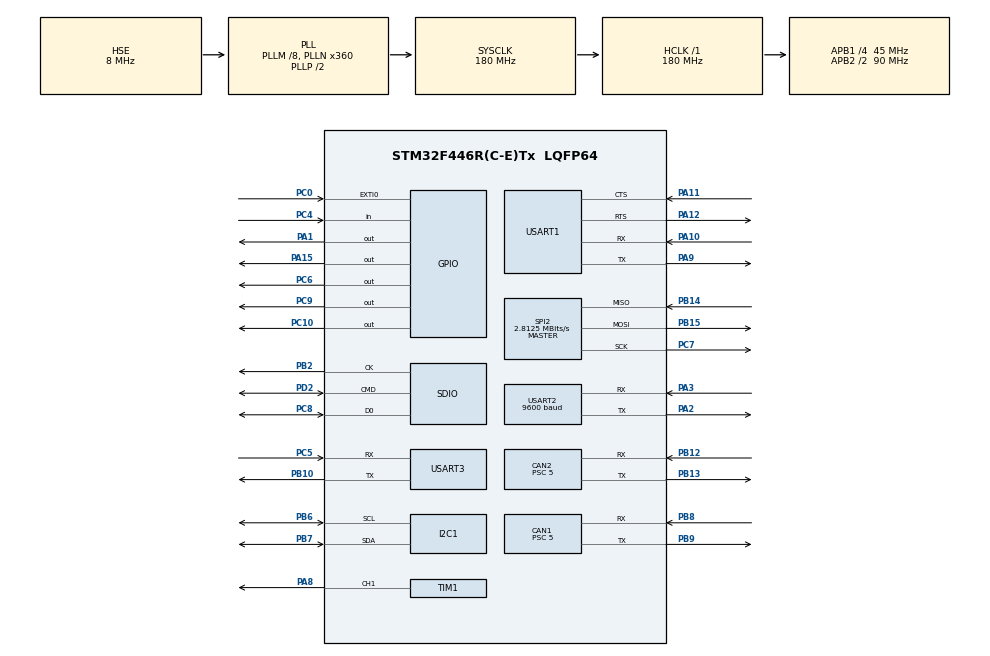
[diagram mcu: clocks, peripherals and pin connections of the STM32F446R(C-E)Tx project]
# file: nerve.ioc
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CAN1.BS1=CAN_BS1_15TQ
CAN1.BS2=CAN_BS2_2TQ
CAN1.CalculateBaudRate=500000
CAN1.CalculateTimeBit=2000
CAN1.CalculateTimeQuantum=111.11111111111111
CAN1.Prescaler=5
CAN2.BS1=CAN_BS1_15TQ
CAN2.BS2=CAN_BS2_2TQ
CAN2.CalculateBaudRate=500000
CAN2.CalculateTimeBit=2000
CAN2.CalculateTimeQuantum=111.11111111111111
CAN2.Prescaler=5
Dma.Request0=SPI2_RX
Dma.Request1=USART1_RX
Dma.Request2=USART1_TX
Dma.Request3=SDIO_RX
Dma.Request4=SDIO_TX
Dma.Request5=TIM1_CH1
Dma.Request6=SPI2_TX
Dma.Request7=USART2_RX
Dma.Request8=USART2_TX
Dma.SDIO_RX.3.Direction=DMA_PERIPH_TO_MEMORY
Dma.SDIO_RX.3.FIFOMode=DMA_FIFOMODE_ENABLE
Dma.SDIO_RX.3.FIFOThreshold=DMA_FIFO_THRESHOLD_FULL
Dma.SDIO_RX.3.Instance=DMA2_Stream3
Dma.SDIO_RX.3.MemBurst=DMA_MBURST_INC4
Dma.SDIO_RX.3.MemDataAlignment=DMA_MDATAALIGN_WORD
Dma.SDIO_RX.3.MemInc=DMA_MINC_ENABLE
Dma.SDIO_RX.3.Mode=DMA_PFCTRL
Dma.SDIO_RX.3.PeriphBurst=DMA_PBURST_INC4
Dma.SDIO_RX.3.PeriphDataAlignment=DMA_PDATAALIGN_WORD
Dma.SDIO_RX.3.PeriphInc=DMA_PINC_DISABLE
Dma.SDIO_RX.3.Priority=DMA_PRIORITY_LOW
Dma.SDIO_TX.4.Direction=DMA_MEMORY_TO_PERIPH
Dma.SDIO_TX.4.FIFOMode=DMA_FIFOMODE_ENABLE
Dma.SDIO_TX.4.FIFOThreshold=DMA_FIFO_THRESHOLD_FULL
Dma.SDIO_TX.4.Instance=DMA2_Stream6
Dma.SDIO_TX.4.MemBurst=DMA_MBURST_INC4
Dma.SDIO_TX.4.MemDataAlignment=DMA_MDATAALIGN_WORD
Dma.SDIO_TX.4.MemInc=DMA_MINC_ENABLE
Dma.SDIO_TX.4.Mode=DMA_PFCTRL
Dma.SDIO_TX.4.PeriphBurst=DMA_PBURST_INC4
Dma.SDIO_TX.4.PeriphDataAlignment=DMA_PDATAALIGN_WORD
Dma.SDIO_TX.4.PeriphInc=DMA_PINC_DISABLE
Dma.SDIO_TX.4.Priority=DMA_PRIORITY_LOW
Dma.SPI2_RX.0.Direction=DMA_PERIPH_TO_MEMORY
Dma.SPI2_RX.0.FIFOMode=DMA_FIFOMODE_DISABLE
Dma.SPI2_RX.0.Instance=DMA1_Stream3
Dma.SPI2_RX.0.MemDataAlignment=DMA_MDATAALIGN_BYTE
Dma.SPI2_RX.0.MemInc=DMA_MINC_ENABLE
Dma.SPI2_RX.0.Mode=DMA_NORMAL
Dma.SPI2_RX.0.PeriphDataAlignment=DMA_PDATAALIGN_BYTE
Dma.SPI2_RX.0.PeriphInc=DMA_PINC_DISABLE
Dma.SPI2_RX.0.Priority=DMA_PRIORITY_LOW
Dma.SPI2_TX.6.Direction=DMA_MEMORY_TO_PERIPH
Dma.SPI2_TX.6.FIFOMode=DMA_FIFOMODE_DISABLE
Dma.SPI2_TX.6.Instance=DMA1_Stream4
Dma.SPI2_TX.6.MemDataAlignment=DMA_MDATAALIGN_BYTE
Dma.SPI2_TX.6.MemInc=DMA_MINC_ENABLE
Dma.SPI2_TX.6.Mode=DMA_NORMAL
Dma.SPI2_TX.6.PeriphDataAlignment=DMA_PDATAALIGN_BYTE
Dma.SPI2_TX.6.PeriphInc=DMA_PINC_DISABLE
Dma.SPI2_TX.6.Priority=DMA_PRIORITY_LOW
Dma.TIM1_CH1.5.Direction=DMA_MEMORY_TO_PERIPH
Dma.TIM1_CH1.5.FIFOMode=DMA_FIFOMODE_DISABLE
Dma.TIM1_CH1.5.Instance=DMA2_Stream1
Dma.TIM1_CH1.5.MemDataAlignment=DMA_MDATAALIGN_HALFWORD
Dma.TIM1_CH1.5.MemInc=DMA_MINC_ENABLE
Dma.TIM1_CH1.5.Mode=DMA_NORMAL
Dma.TIM1_CH1.5.PeriphDataAlignment=DMA_PDATAALIGN_HALFWORD
Dma.TIM1_CH1.5.PeriphInc=DMA_PINC_DISABLE
Dma.TIM1_CH1.5.Priority=DMA_PRIORITY_LOW
Dma.USART1_RX.1.Direction=DMA_PERIPH_TO_MEMORY
Dma.USART1_RX.1.FIFOMode=DMA_FIFOMODE_DISABLE
Dma.USART1_RX.1.Instance=DMA2_Stream2
Dma.USART1_RX.1.MemDataAlignment=DMA_MDATAALIGN_BYTE
Dma.USART1_RX.1.MemInc=DMA_MINC_ENABLE
Dma.USART1_RX.1.Mode=DMA_CIRCULAR
Dma.USART1_RX.1.PeriphDataAlignment=DMA_PDATAALIGN_BYTE
Dma.USART1_RX.1.PeriphInc=DMA_PINC_DISABLE
Dma.USART1_RX.1.Priority=DMA_PRIORITY_HIGH
Dma.USART1_TX.2.Direction=DMA_MEMORY_TO_PERIPH
Dma.USART1_TX.2.FIFOMode=DMA_FIFOMODE_DISABLE
Dma.USART1_TX.2.Instance=DMA2_Stream7
Dma.USART1_TX.2.MemDataAlignment=DMA_MDATAALIGN_BYTE
Dma.USART1_TX.2.MemInc=DMA_MINC_ENABLE
Dma.USART1_TX.2.Mode=DMA_NORMAL
Dma.USART1_TX.2.PeriphDataAlignment=DMA_PDATAALIGN_BYTE
Dma.USART1_TX.2.PeriphInc=DMA_PINC_DISABLE
Dma.USART1_TX.2.Priority=DMA_PRIORITY_HIGH
Dma.USART2_RX.7.Direction=DMA_PERIPH_TO_MEMORY
Dma.USART2_RX.7.FIFOMode=DMA_FIFOMODE_DISABLE
Dma.USART2_RX.7.Instance=DMA1_Stream5
Dma.USART2_RX.7.MemDataAlignment=DMA_MDATAALIGN_BYTE
Dma.USART2_RX.7.MemInc=DMA_MINC_ENABLE
Dma.USART2_RX.7.Mode=DMA_CIRCULAR
Dma.USART2_RX.7.PeriphDataAlignment=DMA_PDATAALIGN_BYTE
Dma.USART2_RX.7.PeriphInc=DMA_PINC_DISABLE
Dma.USART2_RX.7.Priority=DMA_PRIORITY_LOW
Dma.USART2_TX.8.Direction=DMA_MEMORY_TO_PERIPH
Dma.USART2_TX.8.FIFOMode=DMA_FIFOMODE_DISABLE
Dma.USART2_TX.8.Instance=DMA1_Stream6
Dma.USART2_TX.8.MemDataAlignment=DMA_MDATAALIGN_BYTE
Dma.USART2_TX.8.MemInc=DMA_MINC_ENABLE
Dma.USART2_TX.8.Mode=DMA_NORMAL
Dma.USART2_TX.8.PeriphDataAlignment=DMA_PDATAALIGN_BYTE
Dma.USART2_TX.8.PeriphInc=DMA_PINC_DISABLE
Dma.USART2_TX.8.Priority=DMA_PRIORITY_LOW
FATFS.BSP.number=1
FATFS.USE_DMA_CODE_SD=1
FATFS._MAX_SS=4096
FATFS._USE_FIND=1
FATFS._USE_LFN=1
FATFS0.BSP.STBoard=false
FATFS0.BSP.api=Unknown
FATFS0.BSP.instance=PC4
FATFS0.BSP.ip=GPIO
FATFS0.BSP.mode=Input
FATFS0.BSP.name=Detect_SDIO
FATFS0.BSP.solution=PC4
I2C1.I2C_Mode=I2C_Fast
Mcu.Family=STM32F4
Mcu.Name=STM32F446R(C-E)Tx
Mcu.Package=LQFP64
NVIC.CAN1_RX0_IRQn=true\:0\:0\:false\:false\:true\:true\:true\:true
NVIC.CAN1_RX1_IRQn=true\:0\:0\:false\:false\:true\:true\:true\:true
NVIC.CAN2_RX0_IRQn=true\:0\:0\:false\:false\:true\:true\:true\:true
NVIC.CAN2_RX1_IRQn=true\:0\:0\:false\:false\:true\:true\:true\:true
NVIC.DMA1_Stream3_IRQn=true\:1\:1\:true\:false\:true\:false\:true\:true
NVIC.DMA1_Stream4_IRQn=true\:1\:1\:true\:false\:true\:false\:true\:true
NVIC.DMA1_Stream5_IRQn=true\:1\:0\:true\:false\:true\:false\:true\:true
NVIC.DMA1_Stream6_IRQn=true\:1\:0\:true\:false\:true\:false\:true\:true
NVIC.DMA2_Stream1_IRQn=true\:1\:2\:true\:false\:true\:false\:true\:true
NVIC.DMA2_Stream2_IRQn=true\:0\:1\:false\:false\:true\:false\:true\:true
NVIC.DMA2_Stream3_IRQn=true\:0\:0\:false\:false\:true\:false\:true\:true
NVIC.DMA2_Stream6_IRQn=true\:0\:0\:false\:false\:true\:false\:true\:true
NVIC.DMA2_Stream7_IRQn=true\:0\:1\:false\:false\:true\:false\:true\:true
NVIC.EXTI0_IRQn=true\:1\:1\:true\:false\:true\:true\:true\:true
NVIC.PriorityGroup=NVIC_PRIORITYGROUP_1
NVIC.SDIO_IRQn=true\:0\:0\:false\:false\:true\:true\:true\:true
NVIC.TIM1_CC_IRQn=true\:0\:0\:false\:false\:true\:true\:true\:true
NVIC.USART1_IRQn=true\:0\:0\:false\:false\:true\:true\:true\:true
NVIC.USART2_IRQn=true\:1\:0\:true\:false\:true\:true\:true\:true
PA0-WKUP.Mode=SYS_WakeUp0
PA0-WKUP.Signal=SYS_WKUP0
PA1.PinState=GPIO_PIN_SET
PA1.Signal=GPIO_Output
PA10.Mode=Asynchronous
PA10.Signal=USART1_RX
PA11.GPIO_PuPd=GPIO_NOPULL
PA11.Mode=CTS_RTS
PA11.Signal=USART1_CTS
PA12.GPIO_PuPd=GPIO_NOPULL
PA12.Mode=CTS_RTS
PA12.Signal=USART1_RTS
PA13.Mode=Trace_Asynchronous_SW
PA13.Signal=SYS_JTMS-SWDIO
PA14.Mode=Trace_Asynchronous_SW
PA14.Signal=SYS_JTCK-SWCLK
PA15.PinState=GPIO_PIN_SET
PA15.Signal=GPIO_Output
PA2.Mode=Asynchronous
PA2.Signal=USART2_TX
PA3.Mode=Asynchronous
PA3.Signal=USART2_RX
PA8.Signal=S_TIM1_CH1
PA9.Mode=Asynchronous
PA9.Signal=USART1_TX
PB0.Signal=SDIO_D1
PB1.Signal=SDIO_D2
PB10.Mode=Asynchronous
PB10.Signal=USART3_TX
PB12.Mode=CAN_Activate
PB12.Signal=CAN2_RX
PB13.Mode=CAN_Activate
PB13.Signal=CAN2_TX
PB14.Mode=Full_Duplex_Master
PB14.Signal=SPI2_MISO
PB15.Mode=Full_Duplex_Master
PB15.Signal=SPI2_MOSI
PB2.Mode=SD_1_bit
PB2.Signal=SDIO_CK
PB3.Mode=Trace_Asynchronous_SW
PB3.Signal=SYS_JTDO-SWO
PB6.Mode=I2C
PB6.Signal=I2C1_SCL
PB7.Mode=I2C
PB7.Signal=I2C1_SDA
PB8.Mode=CAN_Activate
PB8.Signal=CAN1_RX
PB9.Mode=CAN_Activate
PB9.Signal=CAN1_TX
PC0.GPIO_ModeDefaultEXTI=GPIO_MODE_IT_FALLING
PC0.GPIO_PuPd=GPIO_PULLUP
PC0.Signal=GPXTI0
PC10.PinState=GPIO_PIN_SET
PC10.Signal=GPIO_Output
PC11.Signal=SDIO_D3
PC13.Mode=SYS_WakeUp1
PC13.Signal=SYS_WKUP1
PC14-OSC32_IN.Mode=LSE-External-Oscillator
PC14-OSC32_IN.Signal=RCC_OSC32_IN
PC15-OSC32_OUT.Mode=LSE-External-Oscillator
PC15-OSC32_OUT.Signal=RCC_OSC32_OUT
PC4.Signal=GPIO_Input
PC5.Mode=Asynchronous
PC5.Signal=USART3_RX
PC6.PinState=GPIO_PIN_SET
PC6.Signal=GPIO_Output
PC7.Mode=Full_Duplex_Master
PC7.Signal=SPI2_SCK
PC8.Mode=SD_1_bit
PC8.Signal=SDIO_D0
PC9.PinState=GPIO_PIN_SET
PC9.Signal=GPIO_Output
PD2.Mode=SD_1_bit
PD2.Signal=SDIO_CMD
PH0-OSC_IN.Mode=HSE-External-Oscillator
PH0-OSC_IN.Signal=RCC_OSC_IN
PH1-OSC_OUT.Mode=HSE-External-Oscillator
PH1-OSC_OUT.Signal=RCC_OSC_OUT
ProjectManager.HeapSize=0x200
ProjectManager.StackSize=0x400
ProjectManager.TargetToolchain=STM32CubeIDE
RCC.48MHZClocksFreq_Value=84000000
RCC.AHBFreq_Value=180000000
RCC.APB1CLKDivider=RCC_HCLK_DIV4
RCC.APB1Freq_Value=45000000
RCC.APB1TimFreq_Value=90000000
RCC.APB2CLKDivider=RCC_HCLK_DIV2
RCC.APB2Freq_Value=90000000
RCC.APB2TimFreq_Value=180000000
RCC.CortexFreq_Value=180000000
RCC.FLatency-AdvancedSettings=FLASH_LATENCY_5
RCC.HCLKFreq_Value=180000000
RCC.HSE_VALUE=8000000
RCC.HSI_VALUE=16000000
RCC.PLLM=8
RCC.PLLN=360
RCC.PLLQ=8
RCC.PLLSAIM=4
RCC.PLLSAIN=96
RCC.PLLSAIP=RCC_PLLSAIP_DIV4
RCC.PLLSourceVirtual=RCC_PLLSOURCE_HSE
RCC.SYSCLKFreq_VALUE=180000000
RCC.SYSCLKSource=RCC_SYSCLKSOURCE_PLLCLK
RCC.USBCLockSelection=RCC_CLK48CLKSOURCE_PLLSAIP
RCC.USBFreq_Value=48000000
RCC.VCOOutputFreq_Value=360000000
SDIO.ClockBypass=SDIO_CLOCK_BYPASS_DISABLE
SDIO.ClockDiv=0
SH.S_TIM1_CH1.0=TIM1_CH1,PWM Generation1 CH1
SPI2.BaudRatePrescaler=SPI_BAUDRATEPRESCALER_16
SPI2.CLKPhase=SPI_PHASE_2EDGE
SPI2.CLKPolarity=SPI_POLARITY_HIGH
SPI2.CalculateBaudRate=2.8125 MBits/s
SPI2.Direction=SPI_DIRECTION_2LINES
SPI2.Mode=SPI_MODE_MASTER
SPI2.VirtualType=VM_MASTER
TIM1.Channel-PWM\ Generation1\ CH1=TIM_CHANNEL_1
TIM1.Period=25-1
TIM1.Prescaler=9-1
TIM2.Channel-PWM\ Generation1\ No\ Output=TIM_CHANNEL_1
TIM2.Prescaler=44
TIM5.Channel-PWM\ Generation1\ No\ Output=TIM_CHANNEL_1
TIM5.Prescaler=44
USART1.VirtualMode=VM_ASYNC
USART2.BaudRate=9600
USART2.VirtualMode=VM_ASYNC
USART3.VirtualMode=VM_ASYNC
VP_FATFS_VS_SDIO.Mode=SDIO
VP_RTC_VS_RTC_Activate.Mode=RTC_Enabled
VP_RTC_VS_RTC_Calendar.Mode=RTC_Calendar
VP_TIM2_VS_no_output1.Mode=PWM Generation1 No Output
VP_TIM5_VS_no_output1.Mode=PWM Generation1 No Output
board=NUCLEO-F446RE

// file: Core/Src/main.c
/* USER CODE BEGIN Header */
/**
  ******************************************************************************
  * @file           : main.c
  * @brief          : Main program body
  ******************************************************************************
  * @attention
  *
  * Copyright (c) 2024 STMicroelectronics.
  * All rights reserved.
  *
  * This software is licensed under terms that can be found in the LICENSE file
  * in the root directory of this software component.
  * If no LICENSE file comes with this software, it is provided AS-IS.
  *
  ******************************************************************************
  */
/* USER CODE END Header */
#include "main.h"
#include "fatfs.h"

/* USER CODE BEGIN Includes */
#include "init.h"
#include "run.h"
#include "xbee_api_hal_uart.h"
#include <stdint.h>

#include "configuration.h"
/* USER CODE END Includes */

CAN_HandleTypeDef hcan1;
CAN_HandleTypeDef hcan2;

I2C_HandleTypeDef hi2c1;

RTC_HandleTypeDef hrtc;

SD_HandleTypeDef hsd;
DMA_HandleTypeDef hdma_sdio_rx;
DMA_HandleTypeDef hdma_sdio_tx;

SPI_HandleTypeDef hspi2;
DMA_HandleTypeDef hdma_spi2_rx;
DMA_HandleTypeDef hdma_spi2_tx;

TIM_HandleTypeDef htim1;
TIM_HandleTypeDef htim2;
TIM_HandleTypeDef htim5;
DMA_HandleTypeDef hdma_tim1_ch1;

UART_HandleTypeDef huart1;
UART_HandleTypeDef huart2;
UART_HandleTypeDef huart3;
DMA_HandleTypeDef hdma_usart1_rx;
DMA_HandleTypeDef hdma_usart1_tx;
DMA_HandleTypeDef hdma_usart2_rx;
DMA_HandleTypeDef hdma_usart2_tx;

void SystemClock_Config(void);
static void MX_GPIO_Init(void);
static void MX_DMA_Init(void);
static void MX_USART2_UART_Init(void);
static void MX_CAN1_Init(void);
static void MX_CAN2_Init(void);
static void MX_I2C1_Init(void);
static void MX_SPI2_Init(void);
static void MX_TIM2_Init(void);
static void MX_SDIO_SD_Init(void);
static void MX_TIM5_Init(void);
static void MX_USART3_UART_Init(void);
static void MX_USART1_UART_Init(void);
static void MX_TIM1_Init(void);
static void MX_RTC_Init(void);

int main(void)
{

  /* MCU Configuration--------------------------------------------------------*/

  /* Reset of all peripherals, Initializes the Flash interface and the Systick. */
  HAL_Init();

  /* Configure the system clock */
  SystemClock_Config();

  /* Initialize all configured peripherals */
  MX_GPIO_Init();
  MX_DMA_Init();
  MX_USART2_UART_Init();
  MX_CAN1_Init();
  MX_CAN2_Init();
  MX_I2C1_Init();
  MX_SPI2_Init();
  MX_TIM2_Init();
  MX_SDIO_SD_Init();
  MX_TIM5_Init();
  MX_USART3_UART_Init();
  MX_USART1_UART_Init();
  MX_FATFS_Init();
  MX_TIM1_Init();
  MX_RTC_Init();

  /* Infinite loop */
  /* USER CODE BEGIN WHILE */
  nerve_init();

  while (1) {
    nerve_run();
    /* USER CODE END WHILE */

  }
}

void SystemClock_Config(void)
{
  RCC_OscInitTypeDef RCC_OscInitStruct = {0};
  RCC_ClkInitTypeDef RCC_ClkInitStruct = {0};

  /** Configure the main internal regulator output voltage
  */
  __HAL_RCC_PWR_CLK_ENABLE();
  __HAL_PWR_VOLTAGESCALING_CONFIG(PWR_REGULATOR_VOLTAGE_SCALE1);

  /** Initializes the RCC Oscillators according to the specified parameters
  * in the RCC_OscInitTypeDef structure.
  */
  RCC_OscInitStruct.OscillatorType = RCC_OSCILLATORTYPE_LSI|RCC_OSCILLATORTYPE_HSE;
  RCC_OscInitStruct.HSEState = RCC_HSE_ON;
  RCC_OscInitStruct.LSEState = RCC_LSE_ON;
  RCC_OscInitStruct.LSIState = RCC_LSI_ON;
  RCC_OscInitStruct.PLL.PLLState = RCC_PLL_ON;
  RCC_OscInitStruct.PLL.PLLSource = RCC_PLLSOURCE_HSE;
  RCC_OscInitStruct.PLL.PLLM = 8;
  RCC_OscInitStruct.PLL.PLLN = 360;
  RCC_OscInitStruct.PLL.PLLP = RCC_PLLP_DIV2;
  RCC_OscInitStruct.PLL.PLLQ = 8;
  RCC_OscInitStruct.PLL.PLLR = 2;
  if (HAL_RCC_OscConfig(&RCC_OscInitStruct) != HAL_OK)
  {
    Error_Handler();
  }

  /** Activate the Over-Drive mode
  */
  if (HAL_PWREx_EnableOverDrive() != HAL_OK)
  {
    Error_Handler();
  }

  /** Initializes the CPU, AHB and APB buses clocks
  */
  RCC_ClkInitStruct.ClockType = RCC_CLOCKTYPE_HCLK|RCC_CLOCKTYPE_SYSCLK
                              |RCC_CLOCKTYPE_PCLK1|RCC_CLOCKTYPE_PCLK2;
  RCC_ClkInitStruct.SYSCLKSource = RCC_SYSCLKSOURCE_PLLCLK;
  RCC_ClkInitStruct.AHBCLKDivider = RCC_SYSCLK_DIV1;
  RCC_ClkInitStruct.APB1CLKDivider = RCC_HCLK_DIV4;
  RCC_ClkInitStruct.APB2CLKDivider = RCC_HCLK_DIV2;

  if (HAL_RCC_ClockConfig(&RCC_ClkInitStruct, FLASH_LATENCY_5) != HAL_OK)
  {
    Error_Handler();
  }
}

static void MX_CAN1_Init(void)
{

  hcan1.Instance = CAN1;
  hcan1.Init.Prescaler = 5;
  hcan1.Init.Mode = CAN_MODE_NORMAL;
  hcan1.Init.SyncJumpWidth = CAN_SJW_1TQ;
  hcan1.Init.TimeSeg1 = CAN_BS1_15TQ;
  hcan1.Init.TimeSeg2 = CAN_BS2_2TQ;
  hcan1.Init.TimeTriggeredMode = DISABLE;
  hcan1.Init.AutoBusOff = DISABLE;
  hcan1.Init.AutoWakeUp = DISABLE;
  hcan1.Init.AutoRetransmission = DISABLE;
  hcan1.Init.ReceiveFifoLocked = DISABLE;
  hcan1.Init.TransmitFifoPriority = DISABLE;
  if (HAL_CAN_Init(&hcan1) != HAL_OK)
  {
    Error_Handler();
  }

}

static void MX_CAN2_Init(void)
{

  hcan2.Instance = CAN2;
  hcan2.Init.Prescaler = 5;
  hcan2.Init.Mode = CAN_MODE_NORMAL;
  hcan2.Init.SyncJumpWidth = CAN_SJW_1TQ;
  hcan2.Init.TimeSeg1 = CAN_BS1_15TQ;
  hcan2.Init.TimeSeg2 = CAN_BS2_2TQ;
  hcan2.Init.TimeTriggeredMode = DISABLE;
  hcan2.Init.AutoBusOff = DISABLE;
  hcan2.Init.AutoWakeUp = DISABLE;
  hcan2.Init.AutoRetransmission = DISABLE;
  hcan2.Init.ReceiveFifoLocked = DISABLE;
  hcan2.Init.TransmitFifoPriority = DISABLE;
  if (HAL_CAN_Init(&hcan2) != HAL_OK)
  {
    Error_Handler();
  }

}

static void MX_I2C1_Init(void)
{

  hi2c1.Instance = I2C1;
  hi2c1.Init.ClockSpeed = 400000;
  hi2c1.Init.DutyCycle = I2C_DUTYCYCLE_2;
  hi2c1.Init.OwnAddress1 = 0;
  hi2c1.Init.AddressingMode = I2C_ADDRESSINGMODE_7BIT;
  hi2c1.Init.DualAddressMode = I2C_DUALADDRESS_DISABLE;
  hi2c1.Init.OwnAddress2 = 0;
  hi2c1.Init.GeneralCallMode = I2C_GENERALCALL_DISABLE;
  hi2c1.Init.NoStretchMode = I2C_NOSTRETCH_DISABLE;
  if (HAL_I2C_Init(&hi2c1) != HAL_OK)
  {
    Error_Handler();
  }

}

static void MX_RTC_Init(void)
{

  RTC_TimeTypeDef sTime = {0};
  RTC_DateTypeDef sDate = {0};

  /** Initialize RTC Only
  */
  hrtc.Instance = RTC;
  hrtc.Init.HourFormat = RTC_HOURFORMAT_24;
  hrtc.Init.AsynchPrediv = 127;
  hrtc.Init.SynchPrediv = 255;
  hrtc.Init.OutPut = RTC_OUTPUT_DISABLE;
  hrtc.Init.OutPutPolarity = RTC_OUTPUT_POLARITY_HIGH;
  hrtc.Init.OutPutType = RTC_OUTPUT_TYPE_OPENDRAIN;
  if (HAL_RTC_Init(&hrtc) != HAL_OK)
  {
    Error_Handler();
  }

  /** Initialize RTC and set the Time and Date
  */
  sTime.Hours = 0x0;
  sTime.Minutes = 0x0;
  sTime.Seconds = 0x0;
  sTime.DayLightSaving = RTC_DAYLIGHTSAVING_NONE;
  sTime.StoreOperation = RTC_STOREOPERATION_RESET;
  if (HAL_RTC_SetTime(&hrtc, &sTime, RTC_FORMAT_BCD) != HAL_OK)
  {
    Error_Handler();
  }
  sDate.WeekDay = RTC_WEEKDAY_MONDAY;
  sDate.Month = RTC_MONTH_JANUARY;
  sDate.Date = 0x1;
  sDate.Year = 0x0;

  if (HAL_RTC_SetDate(&hrtc, &sDate, RTC_FORMAT_BCD) != HAL_OK)
  {
    Error_Handler();
  }

}

static void MX_SDIO_SD_Init(void)
{

  hsd.Instance = SDIO;
  hsd.Init.ClockEdge = SDIO_CLOCK_EDGE_RISING;
  hsd.Init.ClockBypass = SDIO_CLOCK_BYPASS_DISABLE;
  hsd.Init.ClockPowerSave = SDIO_CLOCK_POWER_SAVE_DISABLE;
  hsd.Init.BusWide = SDIO_BUS_WIDE_1B;
  hsd.Init.HardwareFlowControl = SDIO_HARDWARE_FLOW_CONTROL_DISABLE;
  hsd.Init.ClockDiv = 0;
  /* USER CODE BEGIN SDIO_Init 2 */
  if (HAL_SD_Init(&hsd) != HAL_OK) {
    Error_Handler();
  }
  if (HAL_SD_ConfigWideBusOperation(&hsd, SDIO_BUS_WIDE_4B) != HAL_OK) {
    Error_Handler();
  }
  /* USER CODE END SDIO_Init 2 */

}

static void MX_SPI2_Init(void)
{

  /* SPI2 parameter configuration*/
  hspi2.Instance = SPI2;
  hspi2.Init.Mode = SPI_MODE_MASTER;
  hspi2.Init.Direction = SPI_DIRECTION_2LINES;
  hspi2.Init.DataSize = SPI_DATASIZE_8BIT;
  hspi2.Init.CLKPolarity = SPI_POLARITY_HIGH;
  hspi2.Init.CLKPhase = SPI_PHASE_2EDGE;
  hspi2.Init.NSS = SPI_NSS_SOFT;
  hspi2.Init.BaudRatePrescaler = SPI_BAUDRATEPRESCALER_16;
  hspi2.Init.FirstBit = SPI_FIRSTBIT_MSB;
  hspi2.Init.TIMode = SPI_TIMODE_DISABLE;
  hspi2.Init.CRCCalculation = SPI_CRCCALCULATION_DISABLE;
  hspi2.Init.CRCPolynomial = 10;
  if (HAL_SPI_Init(&hspi2) != HAL_OK)
  {
    Error_Handler();
  }

}

static void MX_TIM1_Init(void)
{

  TIM_MasterConfigTypeDef sMasterConfig = {0};
  TIM_OC_InitTypeDef sConfigOC = {0};
  TIM_BreakDeadTimeConfigTypeDef sBreakDeadTimeConfig = {0};

  htim1.Instance = TIM1;
  htim1.Init.Prescaler = 9-1;
  htim1.Init.CounterMode = TIM_COUNTERMODE_UP;
  htim1.Init.Period = 25-1;
  htim1.Init.ClockDivision = TIM_CLOCKDIVISION_DIV1;
  htim1.Init.RepetitionCounter = 0;
  htim1.Init.AutoReloadPreload = TIM_AUTORELOAD_PRELOAD_DISABLE;
  if (HAL_TIM_PWM_Init(&htim1) != HAL_OK)
  {
    Error_Handler();
  }
  sMasterConfig.MasterOutputTrigger = TIM_TRGO_RESET;
  sMasterConfig.MasterSlaveMode = TIM_MASTERSLAVEMODE_DISABLE;
  if (HAL_TIMEx_MasterConfigSynchronization(&htim1, &sMasterConfig) != HAL_OK)
  {
    Error_Handler();
  }
  sConfigOC.OCMode = TIM_OCMODE_PWM1;
  sConfigOC.Pulse = 0;
  sConfigOC.OCPolarity = TIM_OCPOLARITY_HIGH;
  sConfigOC.OCNPolarity = TIM_OCNPOLARITY_HIGH;
  sConfigOC.OCFastMode = TIM_OCFAST_DISABLE;
  sConfigOC.OCIdleState = TIM_OCIDLESTATE_RESET;
  sConfigOC.OCNIdleState = TIM_OCNIDLESTATE_RESET;
  if (HAL_TIM_PWM_ConfigChannel(&htim1, &sConfigOC, TIM_CHANNEL_1) != HAL_OK)
  {
    Error_Handler();
  }
  sBreakDeadTimeConfig.OffStateRunMode = TIM_OSSR_DISABLE;
  sBreakDeadTimeConfig.OffStateIDLEMode = TIM_OSSI_DISABLE;
  sBreakDeadTimeConfig.LockLevel = TIM_LOCKLEVEL_OFF;
  sBreakDeadTimeConfig.DeadTime = 0;
  sBreakDeadTimeConfig.BreakState = TIM_BREAK_DISABLE;
  sBreakDeadTimeConfig.BreakPolarity = TIM_BREAKPOLARITY_HIGH;
  sBreakDeadTimeConfig.AutomaticOutput = TIM_AUTOMATICOUTPUT_DISABLE;
  if (HAL_TIMEx_ConfigBreakDeadTime(&htim1, &sBreakDeadTimeConfig) != HAL_OK)
  {
    Error_Handler();
  }
  HAL_TIM_MspPostInit(&htim1);

}

static void MX_TIM2_Init(void)
{

  TIM_MasterConfigTypeDef sMasterConfig = {0};
  TIM_OC_InitTypeDef sConfigOC = {0};

  htim2.Instance = TIM2;
  htim2.Init.Prescaler = 44;
  htim2.Init.CounterMode = TIM_COUNTERMODE_UP;
  htim2.Init.Period = 4294967295;
  htim2.Init.ClockDivision = TIM_CLOCKDIVISION_DIV1;
  htim2.Init.AutoReloadPreload = TIM_AUTORELOAD_PRELOAD_DISABLE;
  if (HAL_TIM_PWM_Init(&htim2) != HAL_OK)
  {
    Error_Handler();
  }
  sMasterConfig.MasterOutputTrigger = TIM_TRGO_RESET;
  sMasterConfig.MasterSlaveMode = TIM_MASTERSLAVEMODE_DISABLE;
  if (HAL_TIMEx_MasterConfigSynchronization(&htim2, &sMasterConfig) != HAL_OK)
  {
    Error_Handler();
  }
  sConfigOC.OCMode = TIM_OCMODE_PWM1;
  sConfigOC.Pulse = 0;
  sConfigOC.OCPolarity = TIM_OCPOLARITY_HIGH;
  sConfigOC.OCFastMode = TIM_OCFAST_DISABLE;
  if (HAL_TIM_PWM_ConfigChannel(&htim2, &sConfigOC, TIM_CHANNEL_1) != HAL_OK)
  {
    Error_Handler();
  }

}

static void MX_TIM5_Init(void)
{

  TIM_MasterConfigTypeDef sMasterConfig = {0};
  TIM_OC_InitTypeDef sConfigOC = {0};

  htim5.Instance = TIM5;
  htim5.Init.Prescaler = 44;
  htim5.Init.CounterMode = TIM_COUNTERMODE_UP;
  htim5.Init.Period = 4294967295;
  htim5.Init.ClockDivision = TIM_CLOCKDIVISION_DIV1;
  htim5.Init.AutoReloadPreload = TIM_AUTORELOAD_PRELOAD_DISABLE;
  if (HAL_TIM_PWM_Init(&htim5) != HAL_OK)
  {
    Error_Handler();
  }
  sMasterConfig.MasterOutputTrigger = TIM_TRGO_RESET;
  sMasterConfig.MasterSlaveMode = TIM_MASTERSLAVEMODE_DISABLE;
  if (HAL_TIMEx_MasterConfigSynchronization(&htim5, &sMasterConfig) != HAL_OK)
  {
    Error_Handler();
  }
  sConfigOC.OCMode = TIM_OCMODE_PWM1;
  sConfigOC.Pulse = 0;
  sConfigOC.OCPolarity = TIM_OCPOLARITY_HIGH;
  sConfigOC.OCFastMode = TIM_OCFAST_DISABLE;
  if (HAL_TIM_PWM_ConfigChannel(&htim5, &sConfigOC, TIM_CHANNEL_1) != HAL_OK)
  {
    Error_Handler();
  }

}

static void MX_USART1_UART_Init(void)
{

  huart1.Instance = USART1;
  huart1.Init.BaudRate = 115200;
  huart1.Init.WordLength = UART_WORDLENGTH_8B;
  huart1.Init.StopBits = UART_STOPBITS_1;
  huart1.Init.Parity = UART_PARITY_NONE;
  huart1.Init.Mode = UART_MODE_TX_RX;
  huart1.Init.HwFlowCtl = UART_HWCONTROL_RTS_CTS;
  huart1.Init.OverSampling = UART_OVERSAMPLING_16;
  if (HAL_UART_Init(&huart1) != HAL_OK)
  {
    Error_Handler();
  }

}

static void MX_USART2_UART_Init(void)
{

  huart2.Instance = USART2;
  huart2.Init.BaudRate = 9600;
  huart2.Init.WordLength = UART_WORDLENGTH_8B;
  huart2.Init.StopBits = UART_STOPBITS_1;
  huart2.Init.Parity = UART_PARITY_NONE;
  huart2.Init.Mode = UART_MODE_TX_RX;
  huart2.Init.HwFlowCtl = UART_HWCONTROL_NONE;
  huart2.Init.OverSampling = UART_OVERSAMPLING_16;
  if (HAL_UART_Init(&huart2) != HAL_OK)
  {
    Error_Handler();
  }

}

static void MX_USART3_UART_Init(void)
{

  huart3.Instance = USART3;
  huart3.Init.BaudRate = 115200;
  huart3.Init.WordLength = UART_WORDLENGTH_8B;
  huart3.Init.StopBits = UART_STOPBITS_1;
  huart3.Init.Parity = UART_PARITY_NONE;
  huart3.Init.Mode = UART_MODE_TX_RX;
  huart3.Init.HwFlowCtl = UART_HWCONTROL_NONE;
  huart3.Init.OverSampling = UART_OVERSAMPLING_16;
  if (HAL_UART_Init(&huart3) != HAL_OK)
  {
    Error_Handler();
  }

}

static void MX_DMA_Init(void)
{

  /* DMA controller clock enable */
  __HAL_RCC_DMA1_CLK_ENABLE();
  __HAL_RCC_DMA2_CLK_ENABLE();

  /* DMA interrupt init */
  /* DMA1_Stream3_IRQn interrupt configuration */
  HAL_NVIC_SetPriority(DMA1_Stream3_IRQn, 1, 1);
  HAL_NVIC_EnableIRQ(DMA1_Stream3_IRQn);
  /* DMA1_Stream4_IRQn interrupt configuration */
  HAL_NVIC_SetPriority(DMA1_Stream4_IRQn, 1, 1);
  HAL_NVIC_EnableIRQ(DMA1_Stream4_IRQn);
  /* DMA1_Stream5_IRQn interrupt configuration */
  HAL_NVIC_SetPriority(DMA1_Stream5_IRQn, 1, 0);
  HAL_NVIC_EnableIRQ(DMA1_Stream5_IRQn);
  /* DMA1_Stream6_IRQn interrupt configuration */
  HAL_NVIC_SetPriority(DMA1_Stream6_IRQn, 1, 0);
  HAL_NVIC_EnableIRQ(DMA1_Stream6_IRQn);
  /* DMA2_Stream1_IRQn interrupt configuration */
  HAL_NVIC_SetPriority(DMA2_Stream1_IRQn, 1, 2);
  HAL_NVIC_EnableIRQ(DMA2_Stream1_IRQn);
  /* DMA2_Stream2_IRQn interrupt configuration */
  HAL_NVIC_SetPriority(DMA2_Stream2_IRQn, 0, 1);
  HAL_NVIC_EnableIRQ(DMA2_Stream2_IRQn);
  /* DMA2_Stream3_IRQn interrupt configuration */
  HAL_NVIC_SetPriority(DMA2_Stream3_IRQn, 0, 0);
  HAL_NVIC_EnableIRQ(DMA2_Stream3_IRQn);
  /* DMA2_Stream6_IRQn interrupt configuration */
  HAL_NVIC_SetPriority(DMA2_Stream6_IRQn, 0, 0);
  HAL_NVIC_EnableIRQ(DMA2_Stream6_IRQn);
  /* DMA2_Stream7_IRQn interrupt configuration */
  HAL_NVIC_SetPriority(DMA2_Stream7_IRQn, 0, 1);
  HAL_NVIC_EnableIRQ(DMA2_Stream7_IRQn);

}

static void MX_GPIO_Init(void)
{
  GPIO_InitTypeDef GPIO_InitStruct = {0};

  /* GPIO Ports Clock Enable */
  __HAL_RCC_GPIOC_CLK_ENABLE();
  __HAL_RCC_GPIOH_CLK_ENABLE();
  __HAL_RCC_GPIOA_CLK_ENABLE();
  __HAL_RCC_GPIOB_CLK_ENABLE();
  __HAL_RCC_GPIOD_CLK_ENABLE();

  /*Configure GPIO pin Output Level */
  HAL_GPIO_WritePin(GPIOA, GPIO_PIN_1|GPIO_PIN_15, GPIO_PIN_SET);

  /*Configure GPIO pin Output Level */
  HAL_GPIO_WritePin(GPIOC, GPIO_PIN_6|GPIO_PIN_9|GPIO_PIN_10, GPIO_PIN_SET);

  /*Configure GPIO pin : PC0 */
  GPIO_InitStruct.Pin = GPIO_PIN_0;
  GPIO_InitStruct.Mode = GPIO_MODE_IT_FALLING;
  GPIO_InitStruct.Pull = GPIO_PULLUP;
  HAL_GPIO_Init(GPIOC, &GPIO_InitStruct);

  /*Configure GPIO pins : PA1 PA15 */
  GPIO_InitStruct.Pin = GPIO_PIN_1|GPIO_PIN_15;
  GPIO_InitStruct.Mode = GPIO_MODE_OUTPUT_PP;
  GPIO_InitStruct.Pull = GPIO_NOPULL;
  GPIO_InitStruct.Speed = GPIO_SPEED_FREQ_LOW;
  HAL_GPIO_Init(GPIOA, &GPIO_InitStruct);

  /*Configure GPIO pin : PC4 */
  GPIO_InitStruct.Pin = GPIO_PIN_4;
  GPIO_InitStruct.Mode = GPIO_MODE_INPUT;
  GPIO_InitStruct.Pull = GPIO_NOPULL;
  HAL_GPIO_Init(GPIOC, &GPIO_InitStruct);

  /*Configure GPIO pins : PC6 PC9 PC10 */
  GPIO_InitStruct.Pin = GPIO_PIN_6|GPIO_PIN_9|GPIO_PIN_10;
  GPIO_InitStruct.Mode = GPIO_MODE_OUTPUT_PP;
  GPIO_InitStruct.Pull = GPIO_NOPULL;
  GPIO_InitStruct.Speed = GPIO_SPEED_FREQ_LOW;
  HAL_GPIO_Init(GPIOC, &GPIO_InitStruct);

  /* EXTI interrupt init*/
  HAL_NVIC_SetPriority(EXTI0_IRQn, 1, 1);
  HAL_NVIC_EnableIRQ(EXTI0_IRQn);

}

void Error_Handler(void)
{
  __disable_irq();
  while (1)
  {
  }
}
